# BL808 register map
File version: 0.1
Registers are access not given, no defined reset value unless marked. A register's access mark holds for its fields unless they carry their own. Offsets are from the block's base; [hi:lo] are bit positions.

## AXI_CTRL_NR3d
Base 0x30012A00
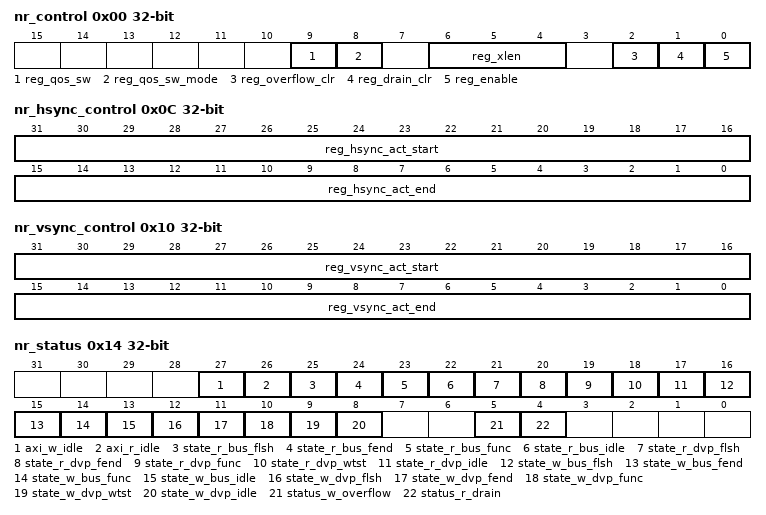
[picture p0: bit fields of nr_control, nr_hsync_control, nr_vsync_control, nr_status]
0x00 nr_control
  [9] reg_qos_sw rw, [8] reg_qos_sw_mode rw, [6:4] reg_xlen rw, [2] reg_overflow_clr write-once, [1] reg_drain_clr write-once, [0] reg_enable rw
0x04 nr_haddr_start_address rw
  [31:0] reg_addr_start
0x08 nr_memory_burst_count rw
  [31:0] reg_burst_cnt
0x0C nr_hsync_control rw
  [31:16] reg_hsync_act_start, [15:0] reg_hsync_act_end
0x10 nr_vsync_control rw
  [31:16] reg_vsync_act_start, [15:0] reg_vsync_act_end
0x14 nr_status
  [27] axi_w_idle ro, [26] axi_r_idle ro, [25] state_r_bus_flsh ro, [24] state_r_bus_fend ro, [23] state_r_bus_func ro, [22] state_r_bus_idle ro, [21] state_r_dvp_flsh ro, [20] state_r_dvp_fend ro, [19] state_r_dvp_func ro, [18] state_r_dvp_wtst ro, [17] state_r_dvp_idle ro, [16] state_w_bus_flsh ro, [15] state_w_bus_fend ro, [14] state_w_bus_func ro, [13] state_w_bus_idle ro, [12] state_w_dvp_flsh ro, [11] state_w_dvp_fend ro, [10] state_w_dvp_func ro, [9] state_w_dvp_wtst ro, [8] state_w_dvp_idle ro, [5] status_w_overflow ro, [4] status_r_drain ro
0xFC nr_RSVD

## DSP2_AWB3_BASE
Base 0x30016000
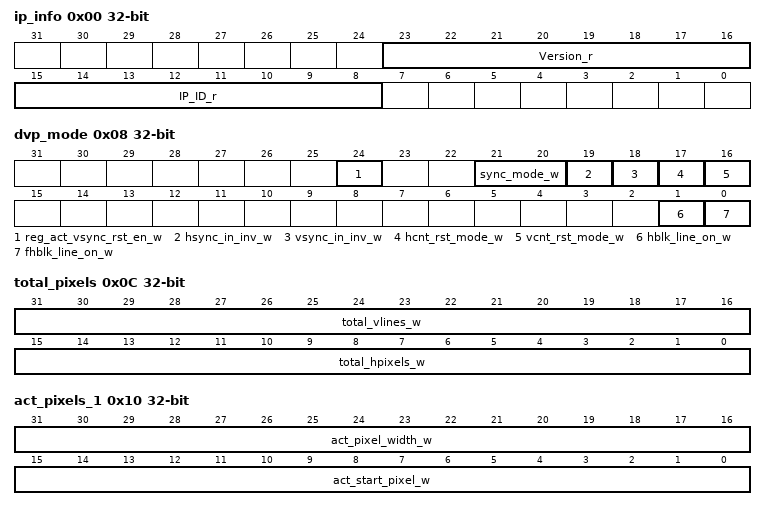
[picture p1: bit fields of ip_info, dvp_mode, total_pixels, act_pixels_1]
0x00 ip_info
  [23:16] Version_r ro, [15:8] IP_ID_r ro
0x08 dvp_mode
  [24] reg_act_vsync_rst_en_w rw, [21:20] sync_mode_w rw, [19] hsync_in_inv_w rw, [18] vsync_in_inv_w rw, [17] hcnt_rst_mode_w rw, [16] vcnt_rst_mode_w rw, [1] hblk_line_on_w rw, [0] fhblk_line_on_w rw
0x0C total_pixels rw
  [31:16] total_vlines_w, [15:0] total_hpixels_w
0x10 act_pixels_1 rw
  [31:16] act_pixel_width_w, [15:0] act_start_pixel_w
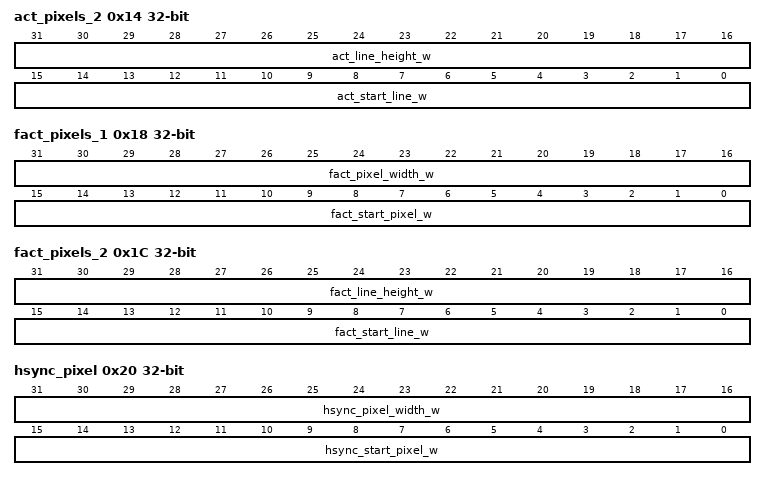
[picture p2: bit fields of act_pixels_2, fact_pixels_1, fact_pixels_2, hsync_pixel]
0x14 act_pixels_2 rw
  [31:16] act_line_height_w, [15:0] act_start_line_w
0x18 fact_pixels_1 rw
  [31:16] fact_pixel_width_w, [15:0] fact_start_pixel_w
0x1C fact_pixels_2 rw
  [31:16] fact_line_height_w, [15:0] fact_start_line_w
0x20 hsync_pixel rw
  [31:16] hsync_pixel_width_w, [15:0] hsync_start_pixel_w
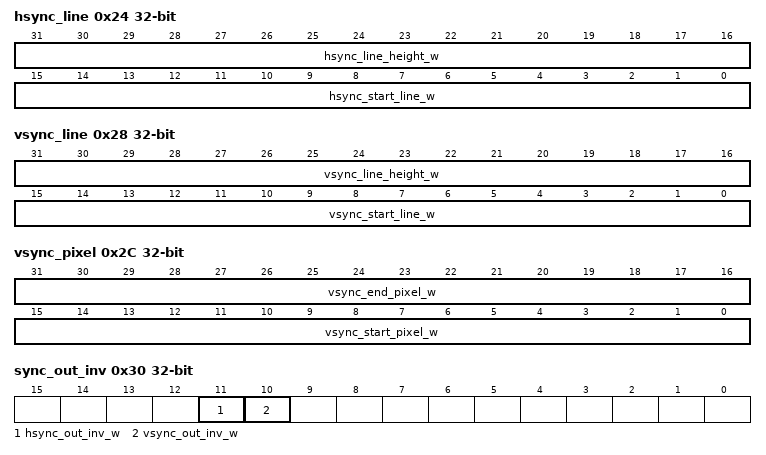
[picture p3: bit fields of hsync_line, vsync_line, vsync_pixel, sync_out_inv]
0x24 hsync_line rw
  [31:16] hsync_line_height_w, [15:0] hsync_start_line_w
0x28 vsync_line rw
  [31:16] vsync_line_height_w, [15:0] vsync_start_line_w
0x2C vsync_pixel rw
  [31:16] vsync_end_pixel_w, [15:0] vsync_start_pixel_w
0x30 sync_out_inv
  [11] hsync_out_inv_w rw, [10] vsync_out_inv_w rw
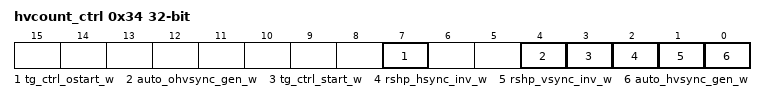
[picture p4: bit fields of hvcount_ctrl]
0x34 hvcount_ctrl
  [7] tg_ctrl_ostart_w write-once, [4] auto_ohvsync_gen_w rw, [3] tg_ctrl_start_w write-once, [2] rshp_hsync_inv_w rw, [1] rshp_vsync_inv_w rw, [0] auto_hvsync_gen_w rw
0xFC dsp2_apb_ctrl
  [15:0] rg_pclk_force_on_w rw

## pSRAM
Base 0x20052000
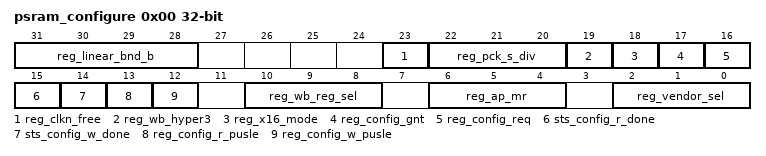
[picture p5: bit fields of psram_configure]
0x00 psram_configure
  [31:28] reg_linear_bnd_b rw — Linear burst boundary shift bit
  [23] reg_clkn_free rw — Clock# free run
  [22:20] reg_pck_s_div rw — EMI AXI bus clock division from psram_ck
  [19] reg_wb_hyper3 rw — Winbond Hyper3 bus
  [18] reg_x16_mode rw — 16-bit pSRAM mode enable
  [17] reg_config_gnt ro — pSRAM register configure grant
  [16] reg_config_req rw — pSRAM register configure request
  [15] sts_config_r_done ro — pSRAM register read done
  [14] sts_config_w_done ro — pSRAM register write done
  [13] reg_config_r_pusle write-once — pSRAM configuration read enable
  [12] reg_config_w_pusle write-once — pSRAM configuration write enable
  [10:8] reg_wb_reg_sel rw — Winbond pSRAM Register R/W selection 3'd0 - ID0 / 3'd1 - ID1 3'd2 - CR0 / 3'd3 - CR1 /3'd4 - CR2 3'd5 - CR3 / 3'd6 - CR4
  [6:4] reg_ap_mr rw — APMemory pSRAM Mode Register R/W selection 3'd0=MA0 / 3'd1=MA1 / 3'd2=MA2 / 3'd3=MA3 / 3'd4=MA4 / 3'd6=MA6 / 3'd7=MA8
  [2:0] reg_vendor_sel rw — pSRAM vendor selection [0] - Winbond [1] - APM_XCELLA [2] - APM_HYPER

## IPC2
Base 0x30005000
Same registers: IPC0 0x2000A8000, IPC1 0x2000A8400
0x00 Interrupt Set Write Register
  [15:0] CPU1_IPC_ISWR wo
0x04 Interrupt raw status Register
  [15:0] CPU1_IPC_IRSRR ro
0x08 Interrupt Clear Register
  [15:0] CPU1_IPC_ICR wo
0x0C Interrupt Unmask Set Register
  [15:0] CPU1_IPC_IUSR ro
0x10 Interrupt Unmask Clear Register
  [15:0] CPU1_IPC_IUCR wo
0x14 Interrupt Line Sel Low Register rw
  [31:0] CPU1_IPC_ILSLR
0x18 Interrupt Line Sel High Register rw
  [31:0] CPU1_IPC_ILSHR
0x1C Interrupt status Register
  [15:0] CPU1_IPC_ISR ro
0x20 Interrupt Set Write Register
  [15:0] CPU0_IPC_ISWR wo
0x24 Interrupt raw status Register
  [15:0] CPU0_IPC_IRSRR ro
0x28 Interrupt Clear Register
  [15:0] CPU0_IPC_ICR wo
0x2C Interrupt Unmask Set Register
  [15:0] CPU0_IPC_IUSR ro
0x30 Interrupt Unmask Clear Register
  [15:0] CPU0_IPC_IUCR ro
0x34 Interrupt Line Sel Low Register rw
  [31:0] CPU0_IPC_ILSLR
0x38 Interrupt Line Sel High Register rw
  [31:0] CPU0_IPC_ILSHR
0x3C Interrupt status Register
  [15:0] CPU0_IPC_ISR ro
